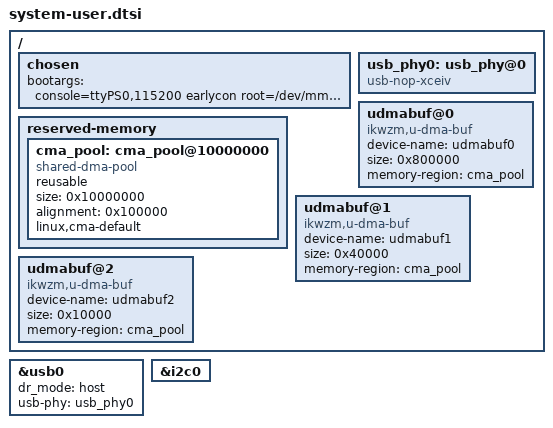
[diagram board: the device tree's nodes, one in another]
/* sw/petalinux/.../device-tree/files/system-user.dtsi
 *
 * User-space additions to the auto-generated tree. The hex addresses MUST
 * stay in sync with hw/vivado/out/address_map.yaml — verified by tests
 * (tools/ci/gen_dts.py + tests/test_address_map.py).
 */

/include/ "system-conf.dtsi"
/include/ "spike-accel.dtsi"      /* PL nodes (C1 owned, sourced from address_map.yaml) */
/include/ "uio_config.dts"        /* auto-generated by tools/ci/gen_dts.py (C2 consumes) */

/ {
    chosen {
        /* isolcpus=1 : isolate Cortex-A9 core 1 from the scheduler so the
         * spike_accel inference-wait thread (C2 SDK) gets jitter-free
         * cycles for IRQ + DMA polling. Core 0 keeps the OS + camera/disp. */
        bootargs = "console=ttyPS0,115200 earlycon root=/dev/mmcblk0p2 rw rootwait cma=256M isolcpus=1";
    };

    /* CMA pool dedicated to spike_accel DMA buffers. */
    reserved-memory {
        #address-cells = <1>;
        #size-cells    = <1>;
        ranges;
        cma_pool: cma_pool@10000000 {
            compatible = "shared-dma-pool";
            reusable;
            size  = <0x10000000>;        /* 256 MB */
            alignment = <0x100000>;
            linux,cma-default;
        };
    };

    /* USB PHY stub for the ZYBO Z7-20 USB OTG port. The Zynq USB controller
     * needs `usb-phy = <&usb_phy0>` to resolve, but the on-board Microchip
     * USB3320C ULPI PHY needs no Linux driver — it initialises itself when
     * the controller starts. usb-nop-xceiv is the standard kernel-builtin
     * stub for that case; the Digilent BSP would normally provide it but
     * we skipped that BSP (8f2e694) so we declare it here
     * (Cloud Claude URGENT_ASK_12 762e8f9, 2026-05-29). */
    usb_phy0: usb_phy@0 {
        compatible = "usb-nop-xceiv";
        #phy-cells = <0>;
    };

    /* u-dma-buf instances backed by the CMA pool. */
    udmabuf@0 {
        compatible = "ikwzm,u-dma-buf";
        device-name = "udmabuf0";
        size = <0x800000>;               /* 8 MB weight pool */
        memory-region = <&cma_pool>;
    };
    udmabuf@1 {
        compatible = "ikwzm,u-dma-buf";
        device-name = "udmabuf1";
        size = <0x40000>;                /* 256 KB input frame */
        memory-region = <&cma_pool>;
    };
    udmabuf@2 {
        compatible = "ikwzm,u-dma-buf";
        device-name = "udmabuf2";
        size = <0x10000>;                /* 64 KB output features */
        memory-region = <&cma_pool>;
    };
};

/* USB OTG in host mode so UVC cameras enumerate as /dev/videoN */
&usb0 {
    status = "okay";
    dr_mode = "host";
    usb-phy = <&usb_phy0>;
};

&i2c0 {
    status = "okay";
};
